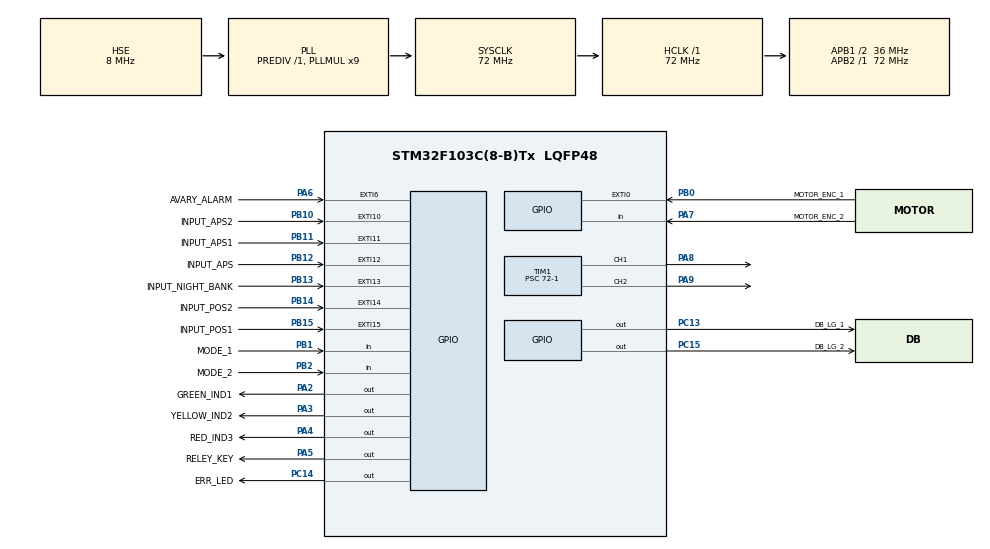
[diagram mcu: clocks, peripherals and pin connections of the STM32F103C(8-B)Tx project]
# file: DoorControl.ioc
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Mcu.Family=STM32F1
Mcu.Name=STM32F103C(8-B)Tx
Mcu.Package=LQFP48
NVIC.EXTI0_IRQn=true\:0\:0\:true\:false\:true\:true\:true\:true
NVIC.EXTI15_10_IRQn=true\:0\:0\:true\:false\:true\:true\:true\:true
NVIC.EXTI9_5_IRQn=true\:0\:0\:true\:false\:true\:true\:true\:true
NVIC.PriorityGroup=NVIC_PRIORITYGROUP_4
NVIC.TIM1_BRK_IRQn=true\:0\:0\:false\:false\:true\:true\:true\:true
NVIC.TIM1_CC_IRQn=true\:0\:0\:false\:false\:true\:true\:true\:true
NVIC.TIM1_TRG_COM_IRQn=true\:0\:0\:false\:false\:true\:true\:true\:true
NVIC.TIM1_UP_IRQn=true\:0\:0\:false\:false\:true\:true\:true\:true
NVIC.TIM3_IRQn=true\:0\:0\:false\:false\:true\:true\:true\:true
NVIC.TIM4_IRQn=true\:1\:0\:true\:false\:true\:true\:true\:true
PA13.Mode=Serial_Wire
PA13.Signal=SYS_JTMS-SWDIO
PA14.Mode=Serial_Wire
PA14.Signal=SYS_JTCK-SWCLK
PA2.GPIO_Label=GREEN_IND1
PA2.Signal=GPIO_Output
PA3.GPIO_Label=YELLOW_IND2
PA3.Signal=GPIO_Output
PA4.GPIO_Label=RED_IND3
PA4.Signal=GPIO_Output
PA5.GPIO_Label=RELEY_KEY
PA5.Signal=GPIO_Output
PA6.GPIO_Label=AVARY_ALARM
PA6.GPIO_ModeDefaultEXTI=GPIO_MODE_IT_FALLING
PA6.GPIO_PuPd=GPIO_PULLDOWN
PA6.Signal=GPXTI6
PA7.GPIO_Label=MOTOR_ENC_2
PA7.GPIO_PuPd=GPIO_PULLDOWN
PA7.Signal=GPIO_Input
PA8.Signal=S_TIM1_CH1
PA9.Signal=S_TIM1_CH2
PB0.GPIO_Label=MOTOR_ENC_1
PB0.GPIO_ModeDefaultEXTI=GPIO_MODE_IT_RISING
PB0.GPIO_PuPd=GPIO_PULLDOWN
PB0.Signal=GPXTI0
PB1.GPIO_Label=MODE_1
PB1.Signal=GPIO_Input
PB10.GPIO_Label=INPUT_APS2
PB10.GPIO_ModeDefaultEXTI=GPIO_MODE_IT_FALLING
PB10.GPIO_PuPd=GPIO_PULLDOWN
PB10.Signal=GPXTI10
PB11.GPIO_Label=INPUT_APS1
PB11.GPIO_ModeDefaultEXTI=GPIO_MODE_IT_FALLING
PB11.GPIO_PuPd=GPIO_PULLDOWN
PB11.Signal=GPXTI11
PB12.GPIO_Label=INPUT_APS
PB12.GPIO_ModeDefaultEXTI=GPIO_MODE_IT_FALLING
PB12.GPIO_PuPd=GPIO_PULLDOWN
PB12.Signal=GPXTI12
PB13.GPIO_Label=INPUT_NIGHT_BANK
PB13.GPIO_ModeDefaultEXTI=GPIO_MODE_IT_FALLING
PB13.GPIO_PuPd=GPIO_PULLDOWN
PB13.Signal=GPXTI13
PB14.GPIO_Label=INPUT_POS2
PB14.GPIO_ModeDefaultEXTI=GPIO_MODE_IT_FALLING
PB14.GPIO_PuPd=GPIO_PULLDOWN
PB14.Signal=GPXTI14
PB15.GPIO_Label=INPUT_POS1
PB15.GPIO_ModeDefaultEXTI=GPIO_MODE_IT_FALLING
PB15.GPIO_PuPd=GPIO_PULLDOWN
PB15.Signal=GPXTI15
PB2.GPIO_Label=MODE_2
PB2.Signal=GPIO_Input
PC13-TAMPER-RTC.GPIO_Label=DB_LG_1
PC13-TAMPER-RTC.Signal=GPIO_Output
PC14-OSC32_IN.GPIO_Label=ERR_LED
PC14-OSC32_IN.Signal=GPIO_Output
PC15-OSC32_OUT.GPIO_Label=DB_LG_2
PC15-OSC32_OUT.Signal=GPIO_Output
PD0-OSC_IN.Mode=HSE-External-Oscillator
PD0-OSC_IN.Signal=RCC_OSC_IN
PD1-OSC_OUT.Mode=HSE-External-Oscillator
PD1-OSC_OUT.Signal=RCC_OSC_OUT
ProjectManager.HeapSize=0x200
ProjectManager.StackSize=0x400
ProjectManager.TargetToolchain=STM32CubeIDE
RCC.ADCPresc=RCC_ADCPCLK2_DIV6
RCC.AHBFreq_Value=72000000
RCC.APB1CLKDivider=RCC_HCLK_DIV2
RCC.APB1Freq_Value=36000000
RCC.APB1TimFreq_Value=72000000
RCC.APB2Freq_Value=72000000
RCC.APB2TimFreq_Value=72000000
RCC.HCLKFreq_Value=72000000
RCC.PLLMUL=RCC_PLL_MUL9
RCC.PLLSourceVirtual=RCC_PLLSOURCE_HSE
RCC.SYSCLKFreq_VALUE=72000000
RCC.SYSCLKSource=RCC_SYSCLKSOURCE_PLLCLK
RCC.USBFreq_Value=72000000
SH.S_TIM1_CH1.0=TIM1_CH1,PWM Generation1 CH1
SH.S_TIM1_CH2.0=TIM1_CH2,PWM Generation2 CH2
TIM1.Channel-PWM\ Generation1\ CH1=TIM_CHANNEL_1
TIM1.Channel-PWM\ Generation2\ CH2=TIM_CHANNEL_2
TIM1.Period=100-1
TIM1.Prescaler=72-1
TIM3.Period=100-1
TIM3.Prescaler=720-1
TIM4.Period=10-1
TIM4.Prescaler=72-1
VP_TIM1_VS_ClockSourceINT.Mode=Internal
VP_TIM3_VS_ClockSourceINT.Mode=Internal
VP_TIM4_VS_ClockSourceINT.Mode=Internal
board=custom

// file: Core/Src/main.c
/* USER CODE BEGIN Header */
/**
  ******************************************************************************
  * @file           : main.c
  * @brief          : Main program body
  ******************************************************************************
  * @attention
  *
  * Copyright (c) 2026 STMicroelectronics.
  * All rights reserved.
  *
  * This software is licensed under terms that can be found in the LICENSE file
  * in the root directory of this software component.
  * If no LICENSE file comes with this software, it is provided AS-IS.
  *
  ******************************************************************************
  */
/* USER CODE END Header */
#include "main.h"

TIM_HandleTypeDef htim1;
TIM_HandleTypeDef htim3;
TIM_HandleTypeDef htim4;

void SystemClock_Config(void);
static void MX_GPIO_Init(void);
static void MX_TIM1_Init(void);
static void MX_TIM4_Init(void);
static void MX_TIM3_Init(void);

int main(void)
{

  /* MCU Configuration--------------------------------------------------------*/

  /* Reset of all peripherals, Initializes the Flash interface and the Systick. */
  HAL_Init();

  /* Configure the system clock */
  SystemClock_Config();

  /* Initialize all configured peripherals */
  MX_GPIO_Init();
  MX_TIM1_Init();
  MX_TIM4_Init();
  MX_TIM3_Init();
  /* USER CODE BEGIN 2 */

  Raspash_Init();

  Raspash_Loop();

  /* USER CODE END 2 */

  /* Infinite loop */
  while (1)
  {

  }
}

void SystemClock_Config(void)
{
  RCC_OscInitTypeDef RCC_OscInitStruct = {0};
  RCC_ClkInitTypeDef RCC_ClkInitStruct = {0};

  /** Initializes the RCC Oscillators according to the specified parameters
  * in the RCC_OscInitTypeDef structure.
  */
  RCC_OscInitStruct.OscillatorType = RCC_OSCILLATORTYPE_HSE;
  RCC_OscInitStruct.HSEState = RCC_HSE_ON;
  RCC_OscInitStruct.HSEPredivValue = RCC_HSE_PREDIV_DIV1;
  RCC_OscInitStruct.HSIState = RCC_HSI_ON;
  RCC_OscInitStruct.PLL.PLLState = RCC_PLL_ON;
  RCC_OscInitStruct.PLL.PLLSource = RCC_PLLSOURCE_HSE;
  RCC_OscInitStruct.PLL.PLLMUL = RCC_PLL_MUL9;
  if (HAL_RCC_OscConfig(&RCC_OscInitStruct) != HAL_OK)
  {
    Error_Handler();
  }

  /** Initializes the CPU, AHB and APB buses clocks
  */
  RCC_ClkInitStruct.ClockType = RCC_CLOCKTYPE_HCLK|RCC_CLOCKTYPE_SYSCLK
                              |RCC_CLOCKTYPE_PCLK1|RCC_CLOCKTYPE_PCLK2;
  RCC_ClkInitStruct.SYSCLKSource = RCC_SYSCLKSOURCE_PLLCLK;
  RCC_ClkInitStruct.AHBCLKDivider = RCC_SYSCLK_DIV1;
  RCC_ClkInitStruct.APB1CLKDivider = RCC_HCLK_DIV2;
  RCC_ClkInitStruct.APB2CLKDivider = RCC_HCLK_DIV1;

  if (HAL_RCC_ClockConfig(&RCC_ClkInitStruct, FLASH_LATENCY_2) != HAL_OK)
  {
    Error_Handler();
  }
}

static void MX_TIM1_Init(void)
{

  TIM_ClockConfigTypeDef sClockSourceConfig = {0};
  TIM_MasterConfigTypeDef sMasterConfig = {0};
  TIM_OC_InitTypeDef sConfigOC = {0};
  TIM_BreakDeadTimeConfigTypeDef sBreakDeadTimeConfig = {0};

  htim1.Instance = TIM1;
  htim1.Init.Prescaler = 72-1;
  htim1.Init.CounterMode = TIM_COUNTERMODE_UP;
  htim1.Init.Period = 100-1;
  htim1.Init.ClockDivision = TIM_CLOCKDIVISION_DIV1;
  htim1.Init.RepetitionCounter = 0;
  htim1.Init.AutoReloadPreload = TIM_AUTORELOAD_PRELOAD_DISABLE;
  if (HAL_TIM_Base_Init(&htim1) != HAL_OK)
  {
    Error_Handler();
  }
  sClockSourceConfig.ClockSource = TIM_CLOCKSOURCE_INTERNAL;
  if (HAL_TIM_ConfigClockSource(&htim1, &sClockSourceConfig) != HAL_OK)
  {
    Error_Handler();
  }
  if (HAL_TIM_PWM_Init(&htim1) != HAL_OK)
  {
    Error_Handler();
  }
  sMasterConfig.MasterOutputTrigger = TIM_TRGO_RESET;
  sMasterConfig.MasterSlaveMode = TIM_MASTERSLAVEMODE_DISABLE;
  if (HAL_TIMEx_MasterConfigSynchronization(&htim1, &sMasterConfig) != HAL_OK)
  {
    Error_Handler();
  }
  sConfigOC.OCMode = TIM_OCMODE_PWM1;
  sConfigOC.Pulse = 0;
  sConfigOC.OCPolarity = TIM_OCPOLARITY_HIGH;
  sConfigOC.OCNPolarity = TIM_OCNPOLARITY_HIGH;
  sConfigOC.OCFastMode = TIM_OCFAST_DISABLE;
  sConfigOC.OCIdleState = TIM_OCIDLESTATE_RESET;
  sConfigOC.OCNIdleState = TIM_OCNIDLESTATE_RESET;
  if (HAL_TIM_PWM_ConfigChannel(&htim1, &sConfigOC, TIM_CHANNEL_1) != HAL_OK)
  {
    Error_Handler();
  }
  if (HAL_TIM_PWM_ConfigChannel(&htim1, &sConfigOC, TIM_CHANNEL_2) != HAL_OK)
  {
    Error_Handler();
  }
  sBreakDeadTimeConfig.OffStateRunMode = TIM_OSSR_DISABLE;
  sBreakDeadTimeConfig.OffStateIDLEMode = TIM_OSSI_DISABLE;
  sBreakDeadTimeConfig.LockLevel = TIM_LOCKLEVEL_OFF;
  sBreakDeadTimeConfig.DeadTime = 0;
  sBreakDeadTimeConfig.BreakState = TIM_BREAK_DISABLE;
  sBreakDeadTimeConfig.BreakPolarity = TIM_BREAKPOLARITY_HIGH;
  sBreakDeadTimeConfig.AutomaticOutput = TIM_AUTOMATICOUTPUT_DISABLE;
  if (HAL_TIMEx_ConfigBreakDeadTime(&htim1, &sBreakDeadTimeConfig) != HAL_OK)
  {
    Error_Handler();
  }
  HAL_TIM_MspPostInit(&htim1);

}

static void MX_TIM3_Init(void)
{

  TIM_ClockConfigTypeDef sClockSourceConfig = {0};
  TIM_MasterConfigTypeDef sMasterConfig = {0};

  htim3.Instance = TIM3;
  htim3.Init.Prescaler = 720-1;
  htim3.Init.CounterMode = TIM_COUNTERMODE_UP;
  htim3.Init.Period = 100-1;
  htim3.Init.ClockDivision = TIM_CLOCKDIVISION_DIV1;
  htim3.Init.AutoReloadPreload = TIM_AUTORELOAD_PRELOAD_DISABLE;
  if (HAL_TIM_Base_Init(&htim3) != HAL_OK)
  {
    Error_Handler();
  }
  sClockSourceConfig.ClockSource = TIM_CLOCKSOURCE_INTERNAL;
  if (HAL_TIM_ConfigClockSource(&htim3, &sClockSourceConfig) != HAL_OK)
  {
    Error_Handler();
  }
  sMasterConfig.MasterOutputTrigger = TIM_TRGO_RESET;
  sMasterConfig.MasterSlaveMode = TIM_MASTERSLAVEMODE_DISABLE;
  if (HAL_TIMEx_MasterConfigSynchronization(&htim3, &sMasterConfig) != HAL_OK)
  {
    Error_Handler();
  }

}

static void MX_TIM4_Init(void)
{

  TIM_ClockConfigTypeDef sClockSourceConfig = {0};
  TIM_MasterConfigTypeDef sMasterConfig = {0};

  htim4.Instance = TIM4;
  htim4.Init.Prescaler = 72-1;
  htim4.Init.CounterMode = TIM_COUNTERMODE_UP;
  htim4.Init.Period = 10-1;
  htim4.Init.ClockDivision = TIM_CLOCKDIVISION_DIV1;
  htim4.Init.AutoReloadPreload = TIM_AUTORELOAD_PRELOAD_DISABLE;
  if (HAL_TIM_Base_Init(&htim4) != HAL_OK)
  {
    Error_Handler();
  }
  sClockSourceConfig.ClockSource = TIM_CLOCKSOURCE_INTERNAL;
  if (HAL_TIM_ConfigClockSource(&htim4, &sClockSourceConfig) != HAL_OK)
  {
    Error_Handler();
  }
  sMasterConfig.MasterOutputTrigger = TIM_TRGO_RESET;
  sMasterConfig.MasterSlaveMode = TIM_MASTERSLAVEMODE_DISABLE;
  if (HAL_TIMEx_MasterConfigSynchronization(&htim4, &sMasterConfig) != HAL_OK)
  {
    Error_Handler();
  }

}

static void MX_GPIO_Init(void)
{
  GPIO_InitTypeDef GPIO_InitStruct = {0};

  /* GPIO Ports Clock Enable */
  __HAL_RCC_GPIOC_CLK_ENABLE();
  __HAL_RCC_GPIOD_CLK_ENABLE();
  __HAL_RCC_GPIOA_CLK_ENABLE();
  __HAL_RCC_GPIOB_CLK_ENABLE();

  /*Configure GPIO pin Output Level */
  HAL_GPIO_WritePin(GPIOC, DB_LG_1_Pin|ERR_LED_Pin|DB_LG_2_Pin, GPIO_PIN_RESET);

  /*Configure GPIO pin Output Level */
  HAL_GPIO_WritePin(GPIOA, GREEN_IND1_Pin|YELLOW_IND2_Pin|RED_IND3_Pin|RELEY_KEY_Pin, GPIO_PIN_RESET);

  /*Configure GPIO pins : DB_LG_1_Pin ERR_LED_Pin DB_LG_2_Pin */
  GPIO_InitStruct.Pin = DB_LG_1_Pin|ERR_LED_Pin|DB_LG_2_Pin;
  GPIO_InitStruct.Mode = GPIO_MODE_OUTPUT_PP;
  GPIO_InitStruct.Pull = GPIO_NOPULL;
  GPIO_InitStruct.Speed = GPIO_SPEED_FREQ_LOW;
  HAL_GPIO_Init(GPIOC, &GPIO_InitStruct);

  /*Configure GPIO pins : GREEN_IND1_Pin YELLOW_IND2_Pin RED_IND3_Pin RELEY_KEY_Pin */
  GPIO_InitStruct.Pin = GREEN_IND1_Pin|YELLOW_IND2_Pin|RED_IND3_Pin|RELEY_KEY_Pin;
  GPIO_InitStruct.Mode = GPIO_MODE_OUTPUT_PP;
  GPIO_InitStruct.Pull = GPIO_NOPULL;
  GPIO_InitStruct.Speed = GPIO_SPEED_FREQ_LOW;
  HAL_GPIO_Init(GPIOA, &GPIO_InitStruct);

  /*Configure GPIO pin : AVARY_ALARM_Pin */
  GPIO_InitStruct.Pin = AVARY_ALARM_Pin;
  GPIO_InitStruct.Mode = GPIO_MODE_IT_FALLING;
  GPIO_InitStruct.Pull = GPIO_PULLDOWN;
  HAL_GPIO_Init(AVARY_ALARM_GPIO_Port, &GPIO_InitStruct);

  /*Configure GPIO pin : MOTOR_ENC_2_Pin */
  GPIO_InitStruct.Pin = MOTOR_ENC_2_Pin;
  GPIO_InitStruct.Mode = GPIO_MODE_INPUT;
  GPIO_InitStruct.Pull = GPIO_PULLDOWN;
  HAL_GPIO_Init(MOTOR_ENC_2_GPIO_Port, &GPIO_InitStruct);

  /*Configure GPIO pin : MOTOR_ENC_1_Pin */
  GPIO_InitStruct.Pin = MOTOR_ENC_1_Pin;
  GPIO_InitStruct.Mode = GPIO_MODE_IT_RISING;
  GPIO_InitStruct.Pull = GPIO_PULLDOWN;
  HAL_GPIO_Init(MOTOR_ENC_1_GPIO_Port, &GPIO_InitStruct);

  /*Configure GPIO pins : MODE_1_Pin MODE_2_Pin */
  GPIO_InitStruct.Pin = MODE_1_Pin|MODE_2_Pin;
  GPIO_InitStruct.Mode = GPIO_MODE_INPUT;
  GPIO_InitStruct.Pull = GPIO_NOPULL;
  HAL_GPIO_Init(GPIOB, &GPIO_InitStruct);

  /*Configure GPIO pins : INPUT_APS2_Pin INPUT_APS1_Pin INPUT_APS_Pin INPUT_NIGHT_BANK_Pin
                           INPUT_POS2_Pin INPUT_POS1_Pin */
  GPIO_InitStruct.Pin = INPUT_APS2_Pin|INPUT_APS1_Pin|INPUT_APS_Pin|INPUT_NIGHT_BANK_Pin
                          |INPUT_POS2_Pin|INPUT_POS1_Pin;
  GPIO_InitStruct.Mode = GPIO_MODE_IT_FALLING;
  GPIO_InitStruct.Pull = GPIO_PULLDOWN;
  HAL_GPIO_Init(GPIOB, &GPIO_InitStruct);

  /* EXTI interrupt init*/
  HAL_NVIC_SetPriority(EXTI0_IRQn, 0, 0);
  HAL_NVIC_EnableIRQ(EXTI0_IRQn);

  HAL_NVIC_SetPriority(EXTI9_5_IRQn, 0, 0);
  HAL_NVIC_EnableIRQ(EXTI9_5_IRQn);

  HAL_NVIC_SetPriority(EXTI15_10_IRQn, 0, 0);
  HAL_NVIC_EnableIRQ(EXTI15_10_IRQn);

}

void Error_Handler(void)
{
  __disable_irq();
  while (1)
  {
  }
}
